# STM32H7A3AGI6Q register map
File version: 1.0
Registers are 32-bit, access not given, reset 0x0 unless marked. A register's access mark holds for its fields unless they carry their own. Offsets are from the block's base; [hi:lo] are bit positions; {n}, {i} and the like mark numbered series; 'fields as' and 'values as' point back to an identical list.

## CEC
Base 0x40006C00
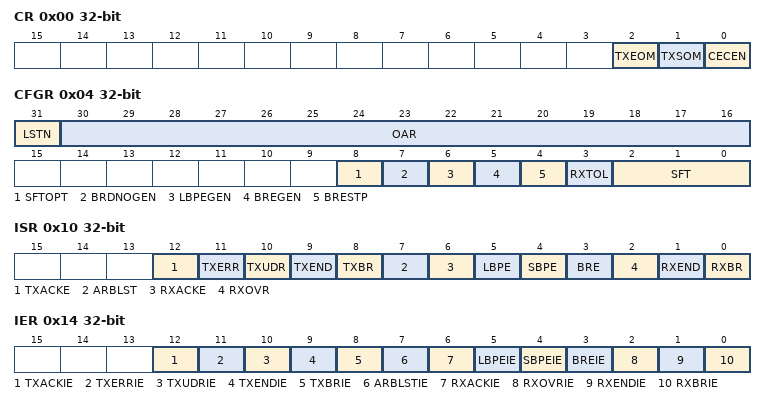
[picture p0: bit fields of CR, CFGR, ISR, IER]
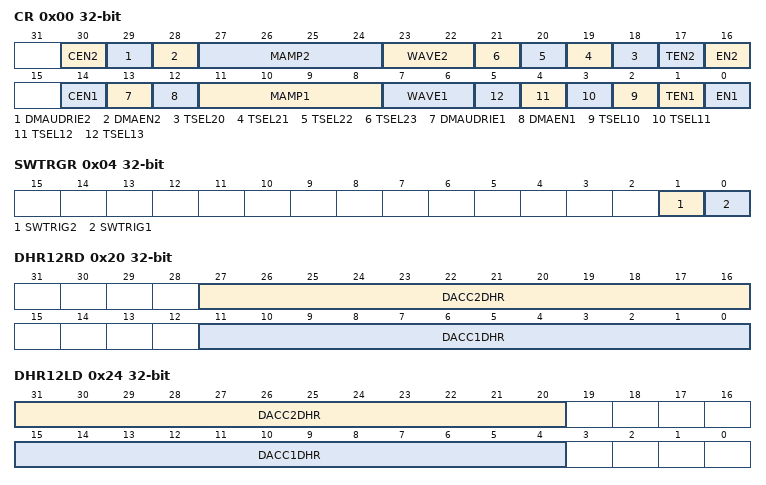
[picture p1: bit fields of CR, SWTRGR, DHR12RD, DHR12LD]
0x00 CR
  [2] TXEOM, [1] TXSOM, [0] CECEN
0x04 CFGR
  [31] LSTN, [30:16] OAR, [8] SFTOPT, [7] BRDNOGEN, [6] LBPEGEN, [5] BREGEN, [4] BRESTP, [3] RXTOL, [2:0] SFT
0x08 TXDR
  [7:0] TXD
0x0C RXDR
  [7:0] RXD
0x10 ISR
  [12] TXACKE, [11] TXERR, [10] TXUDR, [9] TXEND, [8] TXBR, [7] ARBLST, [6] RXACKE, [5] LBPE, [4] SBPE, [3] BRE, [2] RXOVR, [1] RXEND, [0] RXBR
0x14 IER
  [12] TXACKIE, [11] TXERRIE, [10] TXUDRIE, [9] TXENDIE, [8] TXBRIE, [7] ARBLSTIE, [6] RXACKIE, [5] LBPEIE, [4] SBPEIE, [3] BREIE, [2] RXOVRIE, [1] RXENDIE, [0] RXBRIE

## DAC1
Base 0x40007400
Same registers: DAC2 0x58003400
0x00 CR
  [30] CEN2, [29] DMAUDRIE2, [28] DMAEN2, [27:24] MAMP2, [23:22] WAVE2, [n-2] TSEL{n} (n=20..23), [17] TEN2, [16] EN2, [14] CEN1, [13] DMAUDRIE1, [12] DMAEN1, [11:8] MAMP1, [7:6] WAVE1, [n-8] TSEL{n} (n=10..13), [1] TEN1, [0] EN1
0x04 SWTRGR
  [1] SWTRIG2, [0] SWTRIG1
0x08 DHR12R1
  [11:0] DACC1DHR
0x0C DHR12L1
  [15:4] DACC1DHR
0x10 DHR8R1
  [7:0] DACC1DHR
0x14 DHR12R2
  [11:0] DACC2DHR
0x18 DHR12L2
  [15:4] DACC2DHR
0x1C DHR8R2
  [7:0] DACC2DHR
0x20 DHR12RD
  [27:16] DACC2DHR, [11:0] DACC1DHR
0x24 DHR12LD
  [31:20] DACC2DHR, [15:4] DACC1DHR
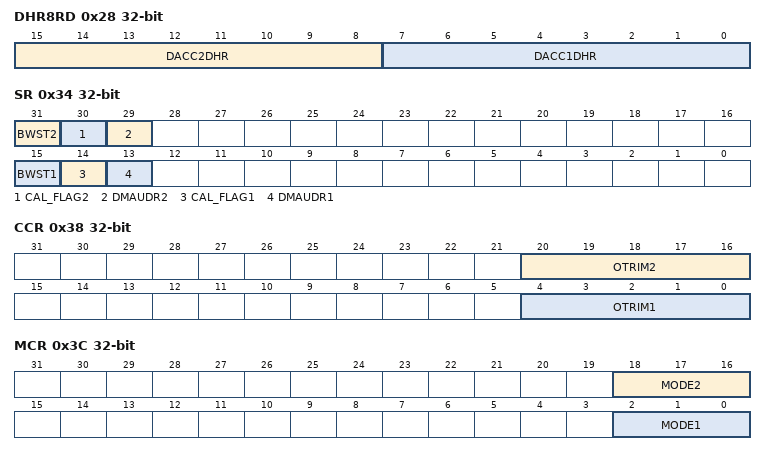
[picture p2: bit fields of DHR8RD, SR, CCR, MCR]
0x28 DHR8RD
  [15:8] DACC2DHR, [7:0] DACC1DHR
0x2C DOR1
  [11:0] DACC1DOR
0x30 DOR2
  [11:0] DACC2DOR
0x34 SR
  [31] BWST2, [30] CAL_FLAG2, [29] DMAUDR2, [15] BWST1, [14] CAL_FLAG1, [13] DMAUDR1
0x38 CCR
  [20:16] OTRIM2, [4:0] OTRIM1
0x3C MCR
  [18:16] MODE2, [2:0] MODE1
0x40 SHSR1
  [9:0] TSAMPLE1
0x44 SHSR2
  [9:0] TSAMPLE2
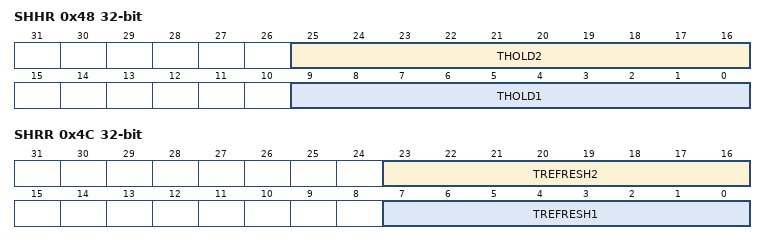
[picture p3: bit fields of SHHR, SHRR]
0x48 SHHR
  [25:16] THOLD2, [9:0] THOLD1
0x4C SHRR
  [23:16] TREFRESH2, [7:0] TREFRESH1

## CRS
Base 0x40008400
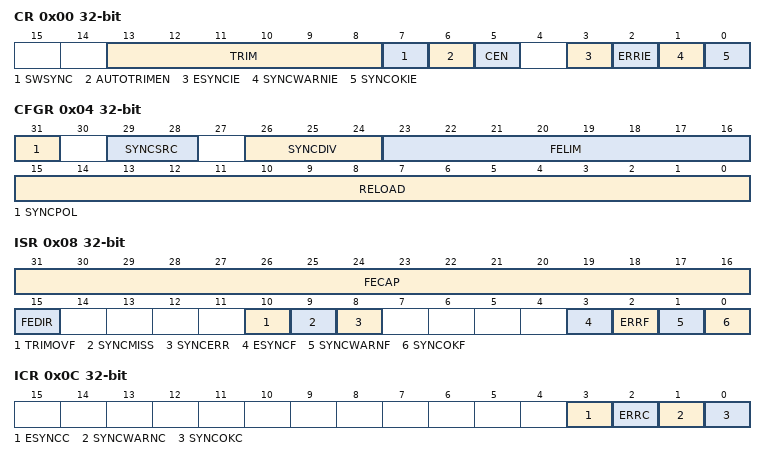
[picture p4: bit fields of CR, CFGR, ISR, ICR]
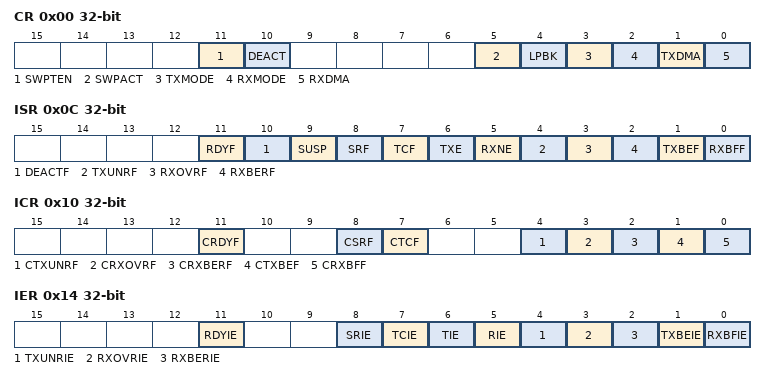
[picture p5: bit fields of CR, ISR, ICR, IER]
0x00 CR
  [13:8] TRIM, [7] SWSYNC, [6] AUTOTRIMEN, [5] CEN, [3] ESYNCIE, [2] ERRIE, [1] SYNCWARNIE, [0] SYNCOKIE
0x04 CFGR
  [31] SYNCPOL, [29:28] SYNCSRC, [26:24] SYNCDIV, [23:16] FELIM, [15:0] RELOAD
0x08 ISR
  [31:16] FECAP, [15] FEDIR, [10] TRIMOVF, [9] SYNCMISS, [8] SYNCERR, [3] ESYNCF, [2] ERRF, [1] SYNCWARNF, [0] SYNCOKF
0x0C ICR
  [3] ESYNCC, [2] ERRC, [1] SYNCWARNC, [0] SYNCOKC

## SWPMI
Base 0x40008800
0x00 CR
  [11] SWPTEN, [10] DEACT, [5] SWPACT, [4] LPBK, [3] TXMODE, [2] RXMODE, [1] TXDMA, [0] RXDMA
0x04 BRR
  [7:0] BRR
0x0C ISR
  [11] RDYF, [10] DEACTF, [9] SUSP, [8] SRF, [7] TCF, [6] TXE, [5] RXNE, [4] TXUNRF, [3] RXOVRF, [2] RXBERF, [1] TXBEF, [0] RXBFF
0x10 ICR
  [11] CRDYF, [8] CSRF, [7] CTCF, [4] CTXUNRF, [3] CRXOVRF, [2] CRXBERF, [1] CTXBEF, [0] CRXBFF
0x14 IER
  [11] RDYIE, [8] SRIE, [7] TCIE, [6] TIE, [5] RIE, [4] TXUNRIE, [3] RXOVRIE, [2] RXBERIE, [1] TXBEIE, [0] RXBFIE
0x18 RFL
  [4:0] RFL
0x1C TDR
  [31:0] TD
0x20 RDR
  [31:0] RD
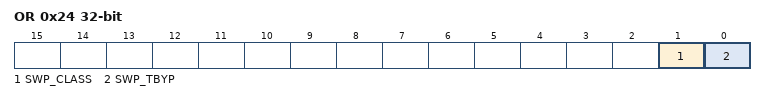
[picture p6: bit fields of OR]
0x24 OR
  [1] SWP_CLASS, [0] SWP_TBYP

## OPAMP
Base 0x40009000
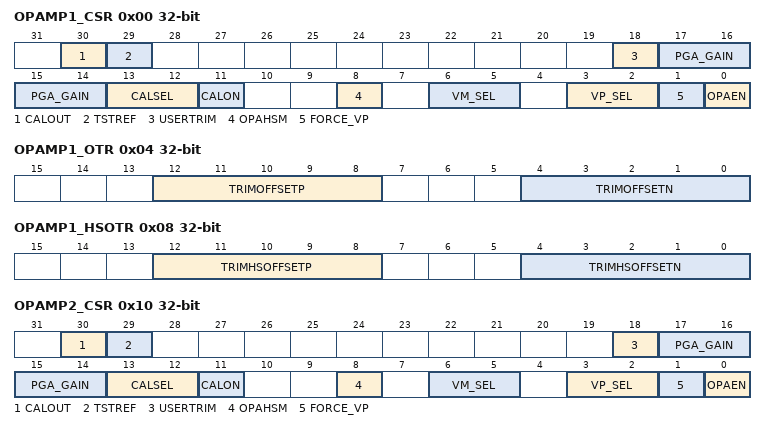
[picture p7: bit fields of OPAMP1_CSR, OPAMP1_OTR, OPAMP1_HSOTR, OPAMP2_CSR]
0x00 OPAMP1_CSR
  [30] CALOUT, [29] TSTREF, [18] USERTRIM, [17:14] PGA_GAIN, [13:12] CALSEL, [11] CALON, [8] OPAHSM, [6:5] VM_SEL, [3:2] VP_SEL, [1] FORCE_VP, [0] OPAEN
0x04 OPAMP1_OTR
  [12:8] TRIMOFFSETP, [4:0] TRIMOFFSETN
0x08 OPAMP1_HSOTR
  [12:8] TRIMHSOFFSETP, [4:0] TRIMHSOFFSETN
0x0C OPAMP_OR
0x10 OPAMP2_CSR
  fields as OPAMP1_CSR
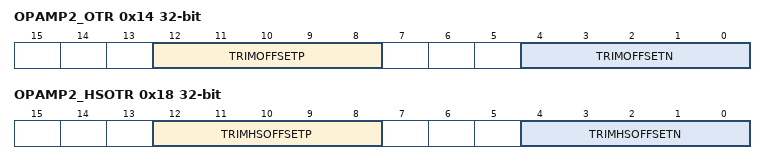
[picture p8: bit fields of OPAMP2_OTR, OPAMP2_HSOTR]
0x14 OPAMP2_OTR
  [12:8] TRIMOFFSETP, [4:0] TRIMOFFSETN
0x18 OPAMP2_HSOTR
  [12:8] TRIMHSOFFSETP, [4:0] TRIMHSOFFSETN

## MDIOS
Base 0x40009400
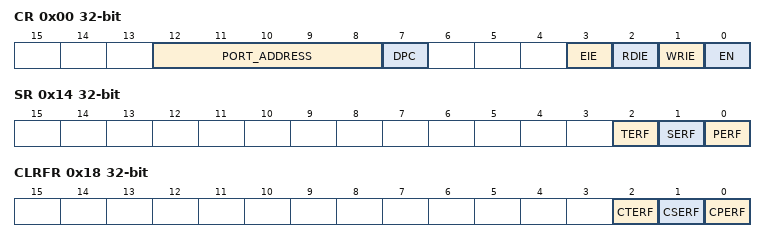
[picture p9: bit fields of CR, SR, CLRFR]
0x00 CR
  [12:8] PORT_ADDRESS, [7] DPC, [3] EIE, [2] RDIE, [1] WRIE, [0] EN
0x04 WRFR
  [31:0] WRF
0x08 CWRFR
  [31:0] CWRF
0x0C RDFR
  [31:0] RDF
0x10 CRDFR
  [31:0] CRDF
0x14 SR
  [2] TERF, [1] SERF, [0] PERF
0x18 CLRFR
  [2] CTERF, [1] CSERF, [0] CPERF
{0x100+4i} DINR{i} (i=0..31)
  [15:0] DIN
{0x180+4i} DOUTR{i} (i=0..31)
  [15:0] DOUT

## FDCAN
Base 0x4000A000
Same registers: FDCAN 0x4000A400, FDCAN 0x4000A400
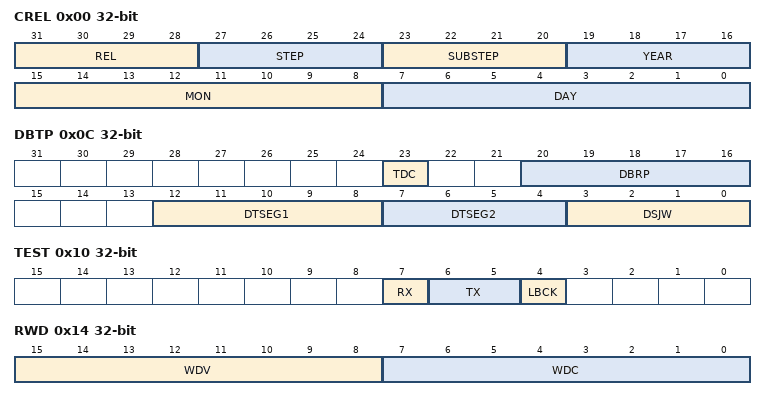
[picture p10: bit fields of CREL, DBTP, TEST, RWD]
0x00 CREL
  [31:28] REL, [27:24] STEP, [23:20] SUBSTEP, [19:16] YEAR, [15:8] MON, [7:0] DAY
0x04 ENDN
  [31:0] ETV
0x0C DBTP
  [23] TDC, [20:16] DBRP, [12:8] DTSEG1, [7:4] DTSEG2, [3:0] DSJW
0x10 TEST
  [7] RX, [6:5] TX, [4] LBCK
0x14 RWD
  [15:8] WDV, [7:0] WDC
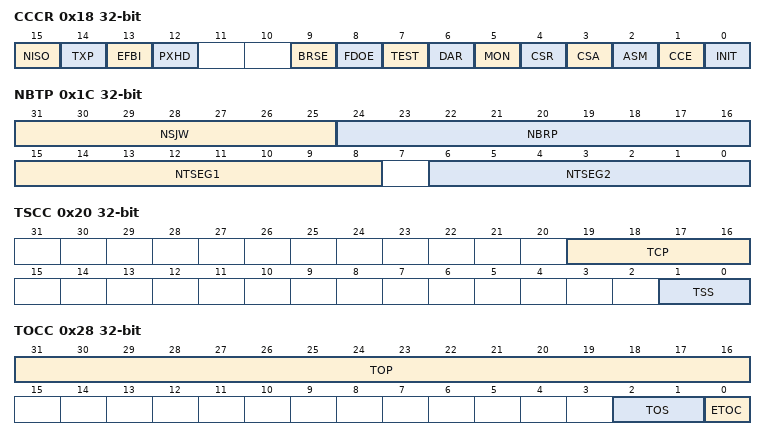
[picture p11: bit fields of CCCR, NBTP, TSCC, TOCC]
0x18 CCCR
  [15] NISO, [14] TXP, [13] EFBI, [12] PXHD, [9] BRSE, [8] FDOE, [7] TEST, [6] DAR, [5] MON, [4] CSR, [3] CSA, [2] ASM, [1] CCE, [0] INIT
0x1C NBTP
  [31:25] NSJW, [24:16] NBRP, [15:8] NTSEG1, [6:0] NTSEG2
0x20 TSCC
  [19:16] TCP, [1:0] TSS
0x24 TSCV
  [15:0] TSC
0x28 TOCC
  [31:16] TOP, [2:1] TOS, [0] ETOC
0x2C TOCV
  [15:0] TOC
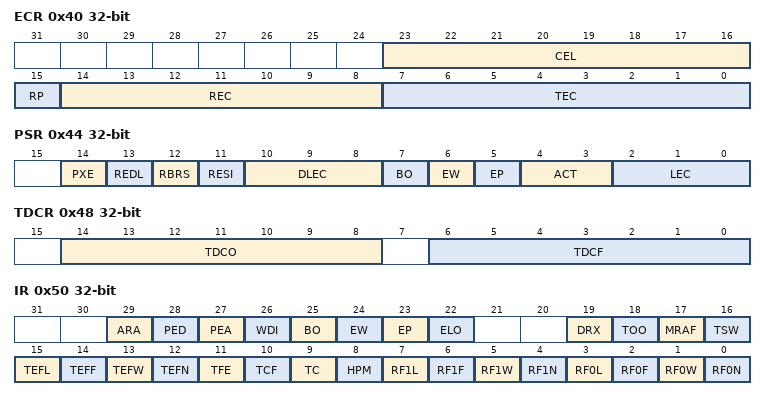
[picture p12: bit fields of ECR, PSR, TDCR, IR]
0x40 ECR
  [23:16] CEL, [15] RP, [14:8] REC, [7:0] TEC
0x44 PSR
  [14] PXE, [13] REDL, [12] RBRS, [11] RESI, [10:8] DLEC, [7] BO, [6] EW, [5] EP, [4:3] ACT, [2:0] LEC
0x48 TDCR
  [14:8] TDCO, [6:0] TDCF
0x50 IR
  [29] ARA, [28] PED, [27] PEA, [26] WDI, [25] BO, [24] EW, [23] EP, [22] ELO, [19] DRX, [18] TOO, [17] MRAF, [16] TSW, [15] TEFL, [14] TEFF, [13] TEFW, [12] TEFN, [11] TFE, [10] TCF, [9] TC, [8] HPM, [7] RF1L, [6] RF1F, [5] RF1W, [4] RF1N, [3] RF0L, [2] RF0F, [1] RF0W, [0] RF0N
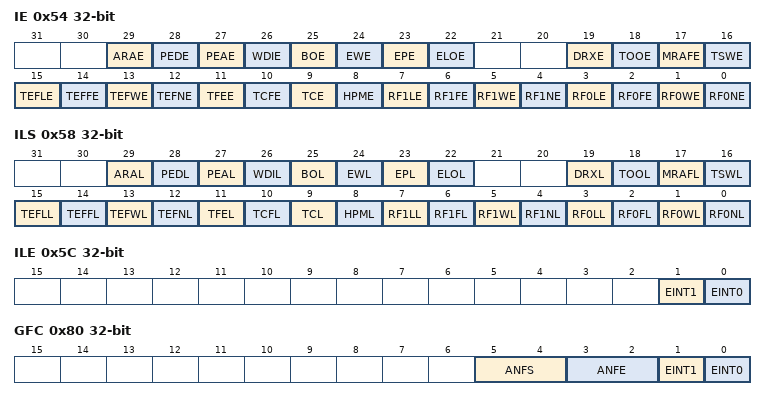
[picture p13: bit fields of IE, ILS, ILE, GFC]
0x54 IE
  [29] ARAE, [28] PEDE, [27] PEAE, [26] WDIE, [25] BOE, [24] EWE, [23] EPE, [22] ELOE, [19] DRXE, [18] TOOE, [17] MRAFE, [16] TSWE, [15] TEFLE, [14] TEFFE, [13] TEFWE, [12] TEFNE, [11] TFEE, [10] TCFE, [9] TCE, [8] HPME, [7] RF1LE, [6] RF1FE, [5] RF1WE, [4] RF1NE, [3] RF0LE, [2] RF0FE, [1] RF0WE, [0] RF0NE
0x58 ILS
  [29] ARAL, [28] PEDL, [27] PEAL, [26] WDIL, [25] BOL, [24] EWL, [23] EPL, [22] ELOL, [19] DRXL, [18] TOOL, [17] MRAFL, [16] TSWL, [15] TEFLL, [14] TEFFL, [13] TEFWL, [12] TEFNL, [11] TFEL, [10] TCFL, [9] TCL, [8] HPML, [7] RF1LL, [6] RF1FL, [5] RF1WL, [4] RF1NL, [3] RF0LL, [2] RF0FL, [1] RF0WL, [0] RF0NL
0x5C ILE
  [1] EINT1, [0] EINT0
0x80 GFC
  [5:4] ANFS, [3:2] ANFE, [1] EINT1, [0] EINT0
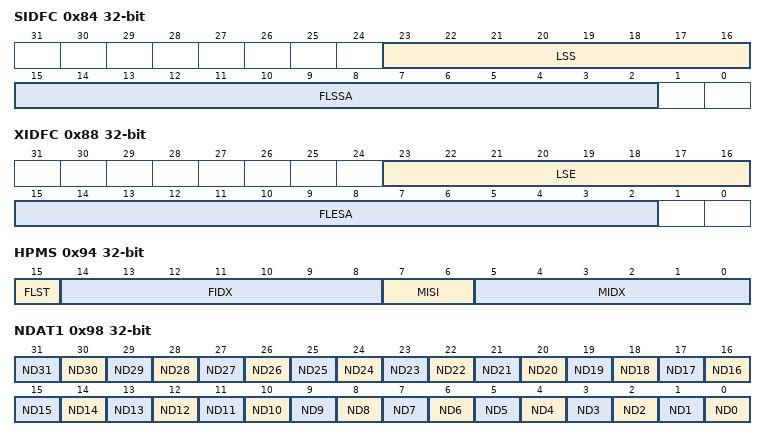
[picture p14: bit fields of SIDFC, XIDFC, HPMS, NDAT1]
0x84 SIDFC
  [23:16] LSS, [15:2] FLSSA
0x88 XIDFC
  [23:16] LSE, [15:2] FLESA
0x90 XIDAM
  [28:0] EIDM
0x94 HPMS
  [15] FLST, [14:8] FIDX, [7:6] MISI, [5:0] MIDX
0x98 NDAT1
  [n] ND{n} (n=0..31)
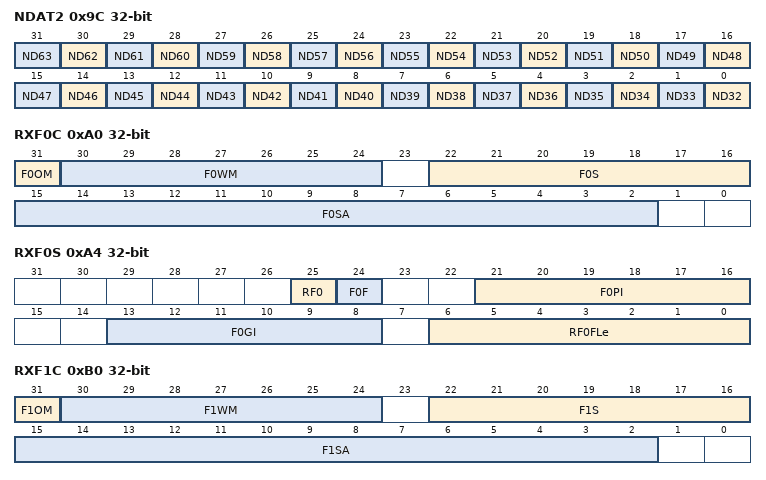
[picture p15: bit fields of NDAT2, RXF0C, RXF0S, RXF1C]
0x9C NDAT2
  [n-32] ND{n} (n=32..63)
0xA0 RXF0C
  [31] F0OM, [30:24] F0WM, [22:16] F0S, [15:2] F0SA
0xA4 RXF0S
  [25] RF0, [24] F0F, [21:16] F0PI, [13:8] F0GI, [6:0] RF0FLe
0xA8 RXF0A
  [5:0] F0AI
0xAC RXBC
  [15:2] RBSA
0xB0 RXF1C
  [31] F1OM, [30:24] F1WM, [22:16] F1S, [15:2] F1SA
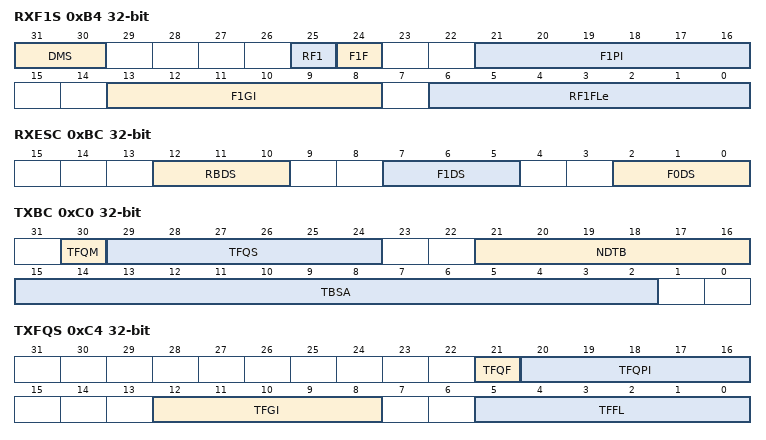
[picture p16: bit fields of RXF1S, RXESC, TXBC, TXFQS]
0xB4 RXF1S
  [31:30] DMS, [25] RF1, [24] F1F, [21:16] F1PI, [13:8] F1GI, [6:0] RF1FLe
0xB8 RXF1A
  [5:0] F1AI
0xBC RXESC
  [12:10] RBDS, [7:5] F1DS, [2:0] F0DS
0xC0 TXBC
  [30] TFQM, [29:24] TFQS, [21:16] NDTB, [15:2] TBSA
0xC4 TXFQS
  [21] TFQF, [20:16] TFQPI, [12:8] TFGI, [5:0] TFFL
0xC8 TXESC
  [2:0] TBDS
0xCC TXBRP
  [n] TRP{n} (n=0..31)
0xD0 TXBAR
  [n] AR{n} (n=0..31)
0xD4 TXBCR
  [n] CR{n} (n=0..31)
0xD8 TXBTO
  [n] TO{n} (n=0..31)
0xDC TXBCF
  [n] CF{n} (n=0..31)
0xE0 TXBTIE
  [n] TIE{n} (n=0..31)
0xE4 TXBCIE
  [n] CFIE{n} (n=0..31)
0xF0 TXEFC
  [29:24] EFWM, [21:16] EFS, [15:2] EFSA
0xF4 TXEFS
  [25] TEF, [24] EFF, [20:16] EFPI, [12:8] EFGI, [5:0] EFFL
0xF8 TXEFA
  [4:0] EFAI
